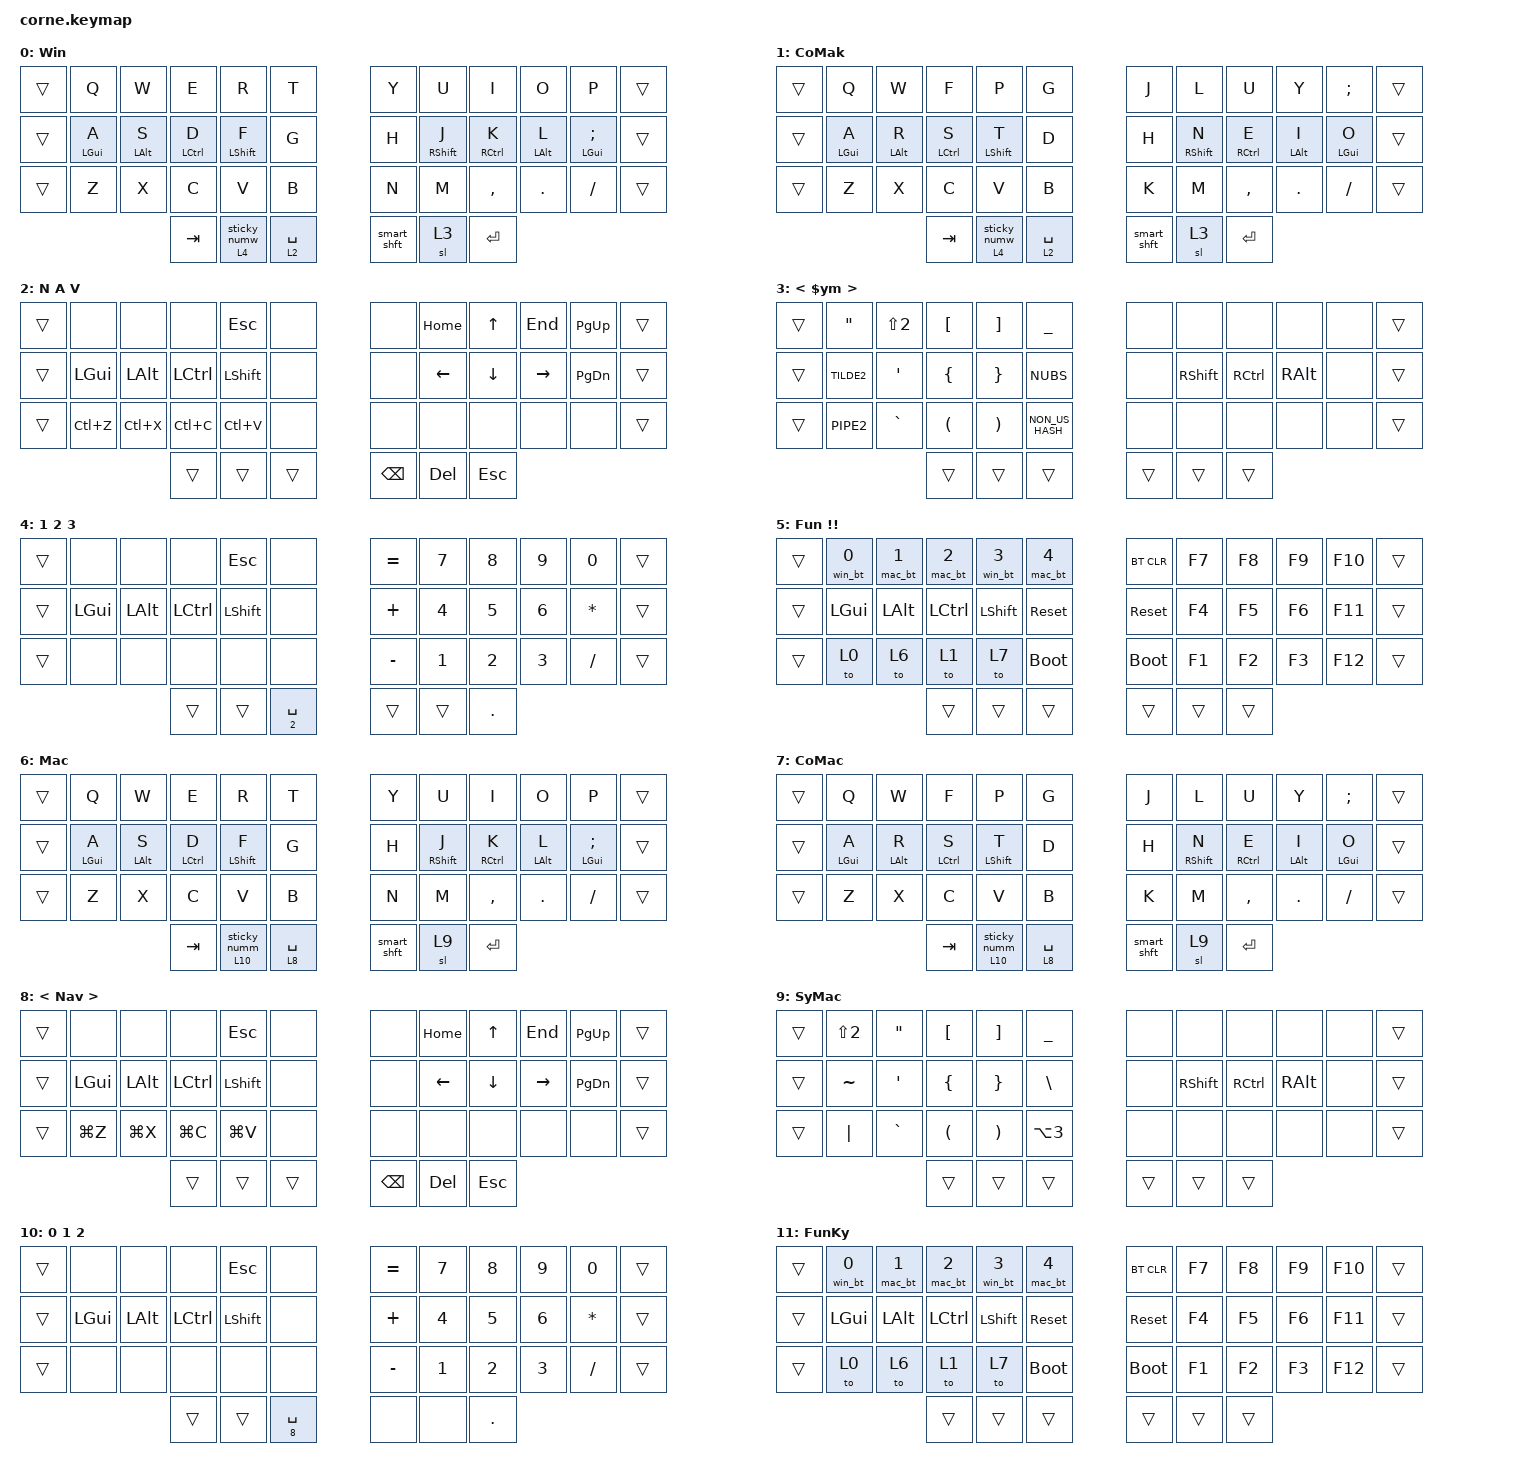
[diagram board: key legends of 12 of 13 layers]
// This has been generated with https://nickcoutsos.github.io/keymap-editor/

#include <behaviors.dtsi>
#include <dt-bindings/zmk/bt.h>
#include <dt-bindings/zmk/keys.h>
#include "mouse.dtsi"

&sk {
    release-after-ms = <900>;  // release after 0.6s
    quick-release;             // no double capitalization when rolling keys
};

&sl {
    ignore-modifiers; // allow chording sitcky mods & layers
    release-after-ms = <900>;  // release after 0.6s
};

&lt {
  flavor = "balanced";
  tapping-term-ms = <200>;
  quick-tap-ms = <175>;
};

&caps_word {
    /delete-property/ ignore-modifiers;  // mods deactivate caps-word, requires PR #1451
};

/ {
    combos {
        compatible = "zmk,combos";

        /*
        db_combo {
            bindings = <&bspc_del>;
            key-positions = <7 8>;
            timeout-ms = <20>;
            require-prior-idle-ms = <120>;
        };

        tab_combo {
            bindings = <&kp TAB>;
            key-positions = <3 4>;
            timeout-ms = <18>;
            require-prior-idle-ms = <200>;
        };

        esc_combo {
            bindings = <&hmr RS(RCTRL) ESC>;
            key-positions = <19 20>;
            timeout-ms = <20>;
            require-prior-idle-ms = <200>;
        };
        */

        cancel {
            bindings = <&hml LS(LCTRL) K_CANCEL>;
            key-positions = <15 16>;
            timeout-ms = <20>;
            require-prior-idle-ms = <150>;
        };

        mouse_combo {
            bindings = <&smart_mouse>;
            key-positions = <2 4>;
            timeout-ms = <20>;
            require-prior-idle-ms = <200>;
        };

        cw_combo {
            bindings = <&caps_word>;
            key-positions = <16 19>;
            layers = <0 6 1 7>;
            timeout-ms = <20>;
            require-prior-idle-ms = <150>;
        };
    };

    macros {
        win_bt: win_bt {
            compatible = "zmk,behavior-macro-one-param";
            #binding-cells = <1>;
            bindings =
                <&macro_param_1to2>,
                <&macro_tap>,
                <&bt BT_SEL MACRO_PLACEHOLDER>,
                <&macro_tap>,
                <&to 0>;
        };

        mac_bt: mac_bt {
            compatible = "zmk,behavior-macro-one-param";
            #binding-cells = <1>;
            bindings =
                <&macro_param_1to2>,
                <&macro_tap>,
                <&bt BT_SEL MACRO_PLACEHOLDER>,
                <&macro_tap>,
                <&to 6>;
        };

        // Special case for the number layer, this issues a cancel before pressing
        // momentary layer to ensure that any sticky num layer is cleared before
        // activating the given layer.
        // This prevents activating the function layer when a sticky number layer is in
        // effect when selecting an arrow key and firing a function key by mistake.

        clr_mo: clr_mo {
            compatible = "zmk,behavior-macro-one-param";
            #binding-cells = <1>;
            bindings =
                <&macro_tap>,
                <&kp K_CANCEL &macro_param_1to1>,
                <&macro_press>,
                <&mo MACRO_PLACEHOLDER>,
                <&macro_pause_for_release>,
                <&macro_param_1to1>,
                <&macro_release>,
                <&mo MACRO_PLACEHOLDER>;

        };
    };

    behaviors {
        bspc_del: backspace_delete {
            compatible = "zmk,behavior-mod-morph";
            #binding-cells = <0>;
            bindings = <&kp BACKSPACE>, <&kp DELETE>;

            mods = <(MOD_LSFT|MOD_RSFT)>;
            keep-mods = <(MOD_LSFT)>;
        };

        // The following mod-morphs only fire on right-shift, which is
        // also smart_shft. A left-shift will use the natural key value
        // Windows GB tap: N3 | rshift-tap: '#' | lshift-tap: LS(N3) = '£'
        w3_hash: three_shift_hash_win {
            compatible = "zmk,behavior-mod-morph";
            #binding-cells = <0>;
            bindings = <&kp N3>, <&kp NON_US_HASH>;

            mods = <(MOD_RSFT)>;
        };

        // Mac GB tap: N3 | rshift-tap: '#' | lshift-tap: LS(N3) = '£'
        m3_hash: three_shift_hash_mac {
            compatible = "zmk,behavior-mod-morph";
            #binding-cells = <0>;
            bindings = <&kp N3>, <&kp LA(N3)>;

            mods = <(MOD_RSFT)>;
        };

        // Windows GB tap: N2 | rshift-tap: '@' | lshift-tap: RS(N2) = '"'
        w2_at: two_shift_at_win {
            compatible = "zmk,behavior-mod-morph";
            #binding-cells = <0>;
            bindings = <&kp N2>, <&kp DQT>;

            mods = <(MOD_RSFT)>;
        };

        hmr: hmr {
            compatible = "zmk,behavior-hold-tap";
            bindings = <&kp>, <&kp>;

            #binding-cells = <2>;
            tapping-term-ms = <280>;
            quick-tap-ms = <175>;
            flavor = "balanced";
            retro-tap;
            hold-trigger-key-positions = <39 40 41 1 2 3 4 5 13 14 15 16 17 25 26 27 28 29 36 37 38>;
            hold-trigger-on-release;
            require-prior-idle-ms = <150>;
        };

        hml: hml {
            compatible = "zmk,behavior-hold-tap";
            bindings = <&kp>, <&kp>;

            #binding-cells = <2>;
            tapping-term-ms = <280>;
            quick-tap-ms = <175>;
            flavor = "balanced";
            retro-tap;
            hold-trigger-key-positions = <36 37 38 6 7 8 9 10 18 19 20 21 22 30 31 32 33 34 39 40 41>;
            hold-trigger-on-release;
            require-prior-idle-ms = <150>;
        };

        smart_shft: smart_shft {
            compatible = "zmk,behavior-mod-morph";
            bindings = <&sk RSHFT>, <&caps_word>;

            #binding-cells = <0>;
            mods = <(MOD_LSFT)>;
        };

        // tap: sticky num-layer | shift-tap: num-word | hold: num-layer

        smart_numw: smart_numw {
            compatible = "zmk,behavior-hold-tap";
            bindings = <&mo>, <&sticky_numw>;

            #binding-cells = <2>;
            tapping-term-ms = <200>;
            flavor = "hold-preferred";
        };

        sticky_numw: sticky_numw {
            compatible = "zmk,behavior-mod-morph";
            #binding-cells = <0>;
            mods = <(MOD_LSFT|MOD_RSFT)>;
            bindings = <&sl 4>, <&num_wordw>;
        };

        num_wordw: num_wordw {
            compatible = "zmk,behavior-caps-word";
            #binding-cells = <0>;
            layers = <4>;
            continue-list = <BSPC DEL DOT MINUS PLUS SQT UNDER>;
            ignore-numbers;
        };

        // tap: sticky num-layer | shift-tap: num-word | hold: num-layer

        smart_numm: smart_numm {
            compatible = "zmk,behavior-hold-tap";
            bindings = <&mo>, <&sticky_numm>;

            #binding-cells = <2>;
            tapping-term-ms = <200>;
            flavor = "hold-preferred";
        };

        sticky_numm: sticky_numm {
            compatible = "zmk,behavior-mod-morph";
            #binding-cells = <0>;
            mods = <(MOD_LSFT|MOD_RSFT)>;
            bindings = <&sl 10>, <&num_wordm>;
        };

        num_wordm: num_wordm {
            compatible = "zmk,behavior-caps-word";
            #binding-cells = <0>;
            layers = <10>;
            continue-list = <BSPC DEL DOT MINUS PLUS SQT UNDER>;
            ignore-numbers;
        };

        smart_mouse: smart_mouse {
            compatible = "zmk,behavior-tri-state";
            bindings = <&tog 12>, <&none>, <&tog 12>;

            #binding-cells = <0>;
            ignored-key-positions = <2 4 7 8 9 13 14 15 16 19 20 21 39 40 41>;
            ignored-layers = <12>;
        };

        // Special case for the number layer, this issues a cancel before pressing
        // momentary layer to ensure that any sticky num layer is cleared before
        // activating the given layer.
        // This prevents activating the function layer when a sticky number layer is in
        // effect when selecting an arrow key and firing a function key by mistake.

        clr_lt: clr_lt {
            compatible = "zmk,behavior-hold-tap";
            bindings = <&clr_mo>, <&kp>;

            #binding-cells = <2>;
            tapping-term-ms = <200>;
            quick-tap-ms = <175>;
            flavor = "tap-preferred";
        };
    };

    keymap {
        compatible = "zmk,keymap";

        win_base {
            bindings = <
&trans  &kp Q        &kp W        &kp E         &kp R            &kp T        &kp Y        &kp U         &kp I         &kp O        &kp P           &trans
&trans  &hml LGUI A  &hml LALT S  &hml LCTRL D  &hml LSHFT F     &kp G        &kp H        &hmr RSHFT J  &hmr RCTRL K  &hmr LALT L  &hmr LGUI SEMI  &trans
&trans  &kp Z        &kp X        &kp C         &kp V            &kp B        &kp N        &kp M         &kp COMMA     &kp DOT      &kp FSLH        &trans
                                  &kp TAB       &smart_numw 4 0  &lt 2 SPACE  &smart_shft  &sl 3         &kp ENTER
            >;

            display-name = "Win";
        };

        win_colemak {
            bindings = <
// Colemak-DH
// &trans  &kp Q        &kp W        &kp F         &kp P            &kp B        &kp J        &kp L         &kp U         &kp Y        &kp SEMI     &trans
// &trans  &hml LGUI A  &hml LALT R  &hml LCTRL S  &hml LSHFT T     &kp G        &kp M        &hmr RSHFT N  &hmr RCTRL E  &hmr LALT I  &hmr LGUI O  &trans
// &trans  &kp Z        &kp X        &kp C         &kp D            &kp V        &kp K        &kp H         &kp COMMA     &kp DOT      &kp FSLH     &trans
// Colemak
&trans  &kp Q        &kp W        &kp F         &kp P            &kp G        &kp J        &kp L         &kp U         &kp Y        &kp SEMI     &trans
&trans  &hml LGUI A  &hml LALT R  &hml LCTRL S  &hml LSHFT T     &kp D        &kp H        &hmr RSHFT N  &hmr RCTRL E  &hmr LALT I  &hmr LGUI O  &trans
&trans  &kp Z        &kp X        &kp C         &kp V            &kp B        &kp K        &kp M         &kp COMMA     &kp DOT      &kp FSLH     &trans
                                  &kp TAB       &smart_numw 4 0  &lt 2 SPACE  &smart_shft  &sl 3         &kp ENTER
            >;

            display-name = "CoMak";
        };

        win_nav {
            bindings = <
&trans  &none      &none      &none      &kp ESCAPE  &none     &none     &kp HOME  &kp UP    &kp END    &kp PG_UP  &trans
&trans  &kp LGUI   &kp LALT   &kp LCTRL  &kp LSHFT   &none     &none     &kp LEFT  &kp DOWN  &kp RIGHT  &kp PG_DN  &trans
&trans  &kp LC(Z)  &kp LC(X)  &kp LC(C)  &kp LC(V)   &none     &none     &none     &none     &none      &none      &trans
                              &trans     &trans      &trans    &kp BSPC  &kp DEL   &kp ESC
            >;

            display-name = "N A V";
        };

        Win_SYM {
            display-name = "< $ym >";
            bindings = <
&trans  &kp DQT     &kp LS(N2)  &kp LBKT  &kp RBKT  &kp UNDER        &none   &none      &none      &none     &none  &trans
&trans  &kp TILDE2  &kp SQT     &kp LBRC  &kp RBRC  &kp NUBS         &none   &kp RSHFT  &kp RCTRL  &kp RALT  &none  &trans
&trans  &kp PIPE2   &kp GRAVE   &kp LPAR  &kp RPAR  &kp NON_US_HASH  &none   &none      &none      &none     &none  &trans
                                &trans    &trans    &trans           &trans  &trans     &trans
            >;
        };

        win_num {
            bindings = <
&trans    &none     &none     &none       &kp ESCAPE  &none            &kp EQUAL  &kp N7   &kp N8   &kp N9  &kp N0     &trans
&trans    &kp LGUI  &kp LALT  &kp LCTRL   &kp LSHFT   &none            &kp PLUS   &kp N4   &kp N5   &kp N6  &kp ASTRK  &trans
&trans    &none     &none     &none       &none       &none            &kp MINUS  &kp N1   &kp N2   &kp N3  &kp SLASH  &trans
// Disable bspc and del until I stop using the num key for the nav functions
//                            &trans      &trans      &clr_lt 2 SPACE  &kp BSPC   &kp DEL  &kp DOT
                              &trans      &trans      &clr_lt 2 SPACE  &trans     &trans   &kp DOT
            >;

            display-name = "1 2 3";
        };

        win_fun {
            bindings = <
&trans  &win_bt 0     &mac_bt 1     &mac_bt 2      &win_bt 3      &mac_bt 4      &bt BT_CLR   &kp F7  &kp F8  &kp F9  &kp F10  &trans
&trans  &kp LGUI      &kp LALT      &kp LCTRL      &kp LSHFT      &sys_reset     &sys_reset   &kp F4  &kp F5  &kp F6  &kp F11  &trans
&trans  &to 0         &to 6         &to 1          &to 7          &bootloader    &bootloader  &kp F1  &kp F2  &kp F3  &kp F12  &trans
                                    &trans         &trans         &trans         &trans       &trans  &trans
            >;

            display-name = "Fun !!";
        };

        mac_base {
            bindings = <
&trans  &kp Q        &kp W        &kp E         &kp R              &kp T         &kp Y        &kp U         &kp I         &kp O        &kp P           &trans
&trans  &hml LGUI A  &hml LALT S  &hml LCTRL D  &hml LSHFT F       &kp G         &kp H        &hmr RSHFT J  &hmr RCTRL K  &hmr LALT L  &hmr LGUI SEMI  &trans
&trans  &kp Z        &kp X        &kp C         &kp V              &kp B         &kp N        &kp M         &kp COMMA     &kp DOT      &kp FSLH        &trans
                                  &kp TAB       &smart_numm 10 0   &lt 8 SPACE   &smart_shft  &sl 9         &kp ENTER
            >;

            display-name = "Mac";
        };

        mac_colemak {
            bindings = <
// Colemak-DH
// &trans  &kp Q        &kp W        &kp F         &kp P             &kp B         &kp J        &kp L         &kp U         &kp Y        &kp SEMI     &trans
// &trans  &hml LGUI A  &hml LALT R  &hml LCTRL S  &hml LSHFT T      &kp G         &kp M        &hmr RSHFT N  &hmr RCTRL E  &hmr LALT I  &hmr LGUI O  &trans
// &trans  &kp Z        &kp X        &kp C         &kp D             &kp V         &kp K        &kp H         &kp COMMA     &kp DOT      &kp FSLH     &trans
// Colemak
&trans  &kp Q        &kp W        &kp F         &kp P             &kp G         &kp J        &kp L         &kp U         &kp Y        &kp SEMI     &trans
&trans  &hml LGUI A  &hml LALT R  &hml LCTRL S  &hml LSHFT T      &kp D         &kp H        &hmr RSHFT N  &hmr RCTRL E  &hmr LALT I  &hmr LGUI O  &trans
&trans  &kp Z        &kp X        &kp C         &kp V             &kp B         &kp K        &kp M         &kp COMMA     &kp DOT      &kp FSLH     &trans
                                  &kp TAB       &smart_numm 10 0  &lt 8 SPACE   &smart_shft  &sl 9         &kp ENTER
            >;

            display-name = "CoMac";
        };

        mac_nav {
            bindings = <
&trans  &none      &none      &none      &kp ESCAPE  &none     &none     &kp HOME  &kp UP    &kp END    &kp PG_UP  &trans
&trans  &kp LGUI   &kp LALT   &kp LCTRL  &kp LSHFT   &none     &none     &kp LEFT  &kp DOWN  &kp RIGHT  &kp PG_DN  &trans
&trans  &kp LG(Z)  &kp LG(X)  &kp LG(C)  &kp LG(V)   &none     &none     &none     &none     &none      &none      &trans
                              &trans     &trans      &trans    &kp BSPC  &kp DEL   &kp ESC
            >;

            display-name = "< Nav >";
        };

        mac_SYM {
            display-name = "SyMac";
            bindings = <
&trans  &kp LS(N2)  &kp DQT    &kp LBKT  &kp RBKT  &kp UNDER   &none   &none      &none      &none     &none  &trans
&trans  &kp TILDE   &kp SQT    &kp LBRC  &kp RBRC  &kp BSLH    &none   &kp RSHFT  &kp RCTRL  &kp RALT  &none  &trans
&trans  &kp PIPE    &kp GRAVE  &kp LPAR  &kp RPAR  &kp LA(N3)  &none   &none      &none      &none     &none  &trans
                               &trans    &trans    &trans      &trans  &trans     &trans
            >;
        };

        mac_num {
            bindings = <
&trans  &none     &none     &none      &kp ESC    &none            &kp EQUAL  &kp N7   &kp N8   &kp N9  &kp N0     &trans
&trans  &kp LGUI  &kp LALT  &kp LCTRL  &kp LSHFT  &none            &kp PLUS   &kp N4   &kp N5   &kp N6  &kp ASTRK  &trans
&trans  &none     &none     &none      &none      &none            &kp MINUS  &kp N1   &kp N2   &kp N3  &kp SLASH  &trans
// Disable bspc and del until I stop using the num key for the nav functions
//                          &trans     &trans     &clr_lt 9 SPACE  &kp BSPC   &kp DEL  &kp DOT
                            &trans     &trans     &clr_lt 8 SPACE  &none      &none    &kp DOT
            >;

            display-name = "0 1 2";
        };

        mac_fun {
            bindings = <
&trans  &win_bt 0     &mac_bt 1     &mac_bt 2      &win_bt 3      &mac_bt 4      &bt BT_CLR   &kp F7  &kp F8  &kp F9  &kp F10  &trans
&trans  &kp LGUI      &kp LALT      &kp LCTRL      &kp LSHFT      &sys_reset     &sys_reset   &kp F4  &kp F5  &kp F6  &kp F11  &trans
&trans  &to 0         &to 6         &to 1          &to 7          &bootloader    &bootloader  &kp F1  &kp F2  &kp F3  &kp F12  &trans
                                    &trans         &trans         &trans         &trans       &trans  &trans
            >;

            display-name = "FunKy";
        };

        mouse {
            bindings = <
&trans     &trans     &trans  &trans                       &trans  &trans    &trans U_WH_D U_MS_U U_WH_U  &trans  &trans  &trans     &kp LGUI   &kp LALT
&kp LCTRL  &kp LSHFT  &trans  &trans U_MS_L U_MS_D U_MS_R  &trans  &trans    &trans                       &trans  &trans  &trans     &trans     &trans
&trans     &trans     &trans  &trans                       &trans  &trans    &trans                       &trans  &trans  &mkp LCLK  &mkp MCLK  &mkp RCLK
            >;

            display-name = "MOUSE";
        };
    };

    conditional_layers {
        compatible = "zmk,conditional-layers";

        ctrl_layer {
            if-layers = <2 4>;
            then-layer = <5>;
        };

        mac_ctrl_layer {
            if-layers = <8 10>;
            then-layer = <11>;
        };
    };
};

